# DMASS_DMSS_CRYPTO_AM61_CFG_CBASS_0_DMASS_DMSS_CRYPTO_AM61_CFG_CBASS_0_FW_450C8000h register map
Vendor: Texas Instruments
Peripheral module from a debugger description file (folder am62L).
Registers are 32-bit, read-write, reset 0x0 unless marked. A register's access mark holds for its fields unless they carry their own. Offsets are as the file gives them; lines under a group give offsets from that group; [hi:lo] are bit positions; {n}, {i} and the like mark numbered series; 'fields as' and 'values as' point back to an identical list; <NAME> marks a mode.

## DMASS_DMSS_CRYPTO_AM61_CFG_CBASS_0_FW
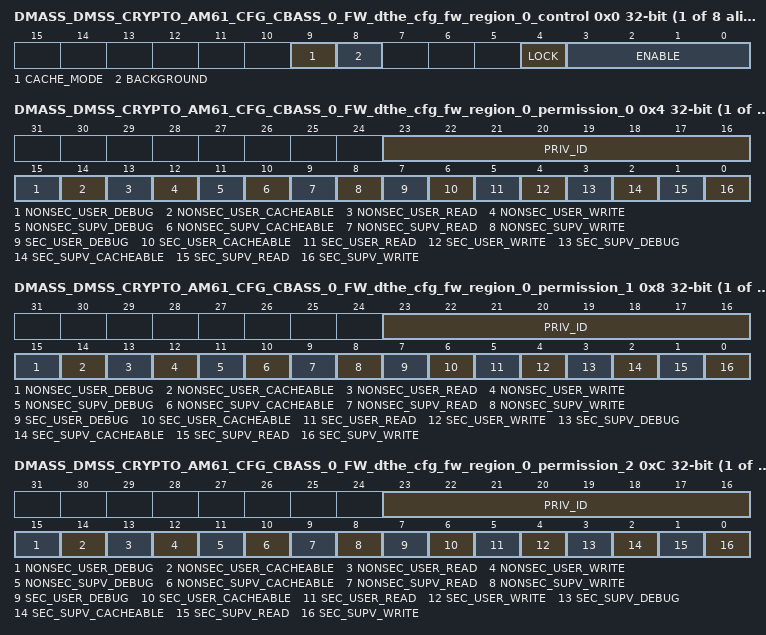
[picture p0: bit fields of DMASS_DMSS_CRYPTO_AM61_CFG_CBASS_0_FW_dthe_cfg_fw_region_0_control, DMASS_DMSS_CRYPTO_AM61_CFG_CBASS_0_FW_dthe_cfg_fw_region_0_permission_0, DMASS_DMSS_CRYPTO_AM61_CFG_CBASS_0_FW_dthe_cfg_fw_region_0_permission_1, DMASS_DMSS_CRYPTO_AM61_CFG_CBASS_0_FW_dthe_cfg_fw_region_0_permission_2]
{0x0+0x20*i} DMASS_DMSS_CRYPTO_AM61_CFG_CBASS_0_FW_dthe_cfg_fw_region_{i}_control access not given (i=0..7) — The FW Region {i} Control Register defines the control fields for the slave dthe.dthe_cfg region {i} firewall.
  [9] CACHE_MODE rw — Cache mode for region. Set to 1 to check cache permissions. Set to 0 to ignore cache permissions. Reset Source: vclk_mod_g_rst_n
  [8] BACKGROUND rw — Background enable for region. There can be 1 backgroun region per FW and foreground regions can have overlapping addresses only with the background region. Reset Source: vclk_mod_g_rst_n
  [4] LOCK — Lock region. Once set region values cannot be modified. Reset Source: vclk_mod_g_rst_n (access R/W1TS)
  [3:0] ENABLE rw — Enable region. A value of 0xA enables, others disable. Reset Source: vclk_mod_g_rst_n
{0x4+0x20*i} DMASS_DMSS_CRYPTO_AM61_CFG_CBASS_0_FW_dthe_cfg_fw_region_{i}_permission_0 (i=0..7) — The FW Region {i} Permission 0 Register defines the permissions for the slave dthe.dthe_cfg region {i} firewall.
  [23:16] PRIV_ID — Allowed privid. Reset Source: vclk_mod_g_rst_n
  [15] NONSEC_USER_DEBUG — Non-secure user debug allowed. Reset Source: vclk_mod_g_rst_n
  [14] NONSEC_USER_CACHEABLE — Non-secure user cacheable allowed. Reset Source: vclk_mod_g_rst_n
  [13] NONSEC_USER_READ — Non-secure user read allowed. Reset Source: vclk_mod_g_rst_n
  [12] NONSEC_USER_WRITE — Non-secure user write allowed. Reset Source: vclk_mod_g_rst_n
  [11] NONSEC_SUPV_DEBUG — Non-secure supervisor debug allowed. Reset Source: vclk_mod_g_rst_n
  [10] NONSEC_SUPV_CACHEABLE — Non-secure supervisor cacheable allowed. Reset Source: vclk_mod_g_rst_n
  [9] NONSEC_SUPV_READ — Non-secure supervisor read allowed. Reset Source: vclk_mod_g_rst_n
  [8] NONSEC_SUPV_WRITE — Non-secure supervisor write allowed. Reset Source: vclk_mod_g_rst_n
  [7] SEC_USER_DEBUG — Secure user debug allowed. Reset Source: vclk_mod_g_rst_n
  [6] SEC_USER_CACHEABLE — Secure user cacheable allowed. Reset Source: vclk_mod_g_rst_n
  [5] SEC_USER_READ — Secure user read allowed. Reset Source: vclk_mod_g_rst_n
  [4] SEC_USER_WRITE — Secure user write allowed. Reset Source: vclk_mod_g_rst_n
  [3] SEC_SUPV_DEBUG — Secure supervisor debug allowed. Reset Source: vclk_mod_g_rst_n
  [2] SEC_SUPV_CACHEABLE — Secure supervisor cacheable allowed. Reset Source: vclk_mod_g_rst_n
  [1] SEC_SUPV_READ — Secure supervisor read allowed. Reset Source: vclk_mod_g_rst_n
  [0] SEC_SUPV_WRITE — Secure supervisor write allowed. Reset Source: vclk_mod_g_rst_n
{0x8+0x20*i} DMASS_DMSS_CRYPTO_AM61_CFG_CBASS_0_FW_dthe_cfg_fw_region_{i}_permission_1 (i=0..7) — The FW Region {i} Permission 1 Register defines the permissions for the slave dthe.dthe_cfg region {i} firewall.
  fields as DMASS_DMSS_CRYPTO_AM61_CFG_CBASS_0_FW_dthe_cfg_fw_region_0_permission_0
{0xC+0x20*i} DMASS_DMSS_CRYPTO_AM61_CFG_CBASS_0_FW_dthe_cfg_fw_region_{i}_permission_2 (i=0..7) — The FW Region {i} Permission 2 Register defines the permissions for the slave dthe.dthe_cfg region {i} firewall.
  fields as DMASS_DMSS_CRYPTO_AM61_CFG_CBASS_0_FW_dthe_cfg_fw_region_0_permission_0
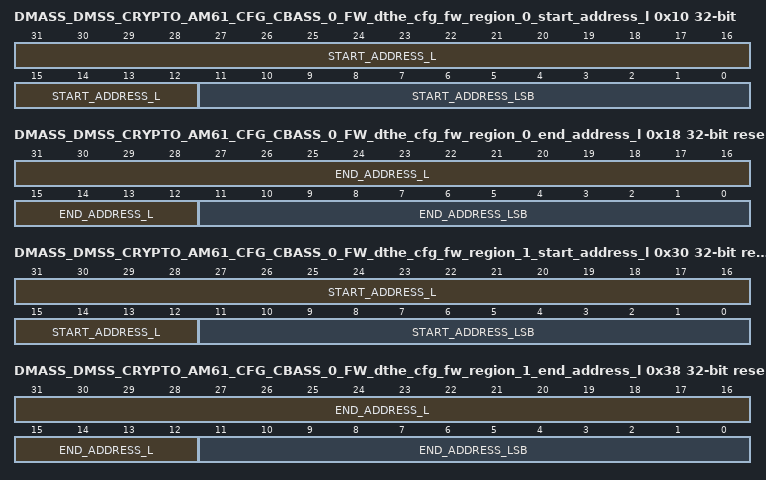
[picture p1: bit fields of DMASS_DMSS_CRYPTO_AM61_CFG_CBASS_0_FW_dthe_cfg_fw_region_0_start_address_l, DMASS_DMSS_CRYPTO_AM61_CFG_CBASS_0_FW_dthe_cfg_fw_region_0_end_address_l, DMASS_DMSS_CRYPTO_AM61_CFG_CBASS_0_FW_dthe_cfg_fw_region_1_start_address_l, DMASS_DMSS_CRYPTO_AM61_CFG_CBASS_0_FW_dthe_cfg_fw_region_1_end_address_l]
0x10 DMASS_DMSS_CRYPTO_AM61_CFG_CBASS_0_FW_dthe_cfg_fw_region_0_start_address_l access per field — The FW Region 0 Start Address Low Register defines the start address bits 31 to 0 for the slave dthe.dthe_cfg region 0 firewall.
  [31:12] START_ADDRESS_L rw — Start address bits 31 to 12. Lowest 12 bits are forced to 0 as address must be 4KB aligned. Reset Source: vclk_mod_g_rst_n
  [11:0] START_ADDRESS_LSB ro — Start address bits 11 to 0 are forced to 0 as address must be 4KB aligned. Reset Source: vclk_mod_g_rst_n
{0x14+0x20*i} DMASS_DMSS_CRYPTO_AM61_CFG_CBASS_0_FW_dthe_cfg_fw_region_{i}_start_address_h (i=0..7) — The FW Region {i} Start Address High Register defines the start address bits 47 to 32 for the slave dthe.dthe_cfg region {i} firewall.
  [15:0] START_ADDRESS_H — Start address bits 47 to 32. Reset Source: vclk_mod_g_rst_n
0x18 DMASS_DMSS_CRYPTO_AM61_CFG_CBASS_0_FW_dthe_cfg_fw_region_0_end_address_l access per field reset 0xFFF — The FW Region 0 End Address Low Register defines the end address bits 31 to 0 to include for the slave dthe.dthe_cfg region 0 firewall.
  [31:12] END_ADDRESS_L rw — End address bits 31 to 12 to include in the match. Lowest 12 bits are forced to 1s as address must be 4KB aligned. Reset Source: vclk_mod_g_rst_n
  [11:0] END_ADDRESS_LSB ro — End address bits 11 to 0 are forced to 1s as address must be 4KB aligned minus 1. Reset Source: vclk_mod_g_rst_n
{0x1C+0x20*i} DMASS_DMSS_CRYPTO_AM61_CFG_CBASS_0_FW_dthe_cfg_fw_region_{i}_end_address_h (i=0..7) — The FW Region {i} End Address High Register defines the end address bits 47 to 32 to include for the slave dthe.dthe_cfg region {i} firewall.
  [15:0] END_ADDRESS_H — End address bits 47 to 32 to include in the match. Reset Source: vclk_mod_g_rst_n
0x30 DMASS_DMSS_CRYPTO_AM61_CFG_CBASS_0_FW_dthe_cfg_fw_region_1_start_address_l access per field reset 0x1000 — The FW Region 1 Start Address Low Register defines the start address bits 31 to 0 for the slave dthe.dthe_cfg region 1 firewall.
  fields as DMASS_DMSS_CRYPTO_AM61_CFG_CBASS_0_FW_dthe_cfg_fw_region_0_start_address_l
0x38 DMASS_DMSS_CRYPTO_AM61_CFG_CBASS_0_FW_dthe_cfg_fw_region_1_end_address_l access per field reset 0x1FFF — The FW Region 1 End Address Low Register defines the end address bits 31 to 0 to include for the slave dthe.dthe_cfg region 1 firewall.
  fields as DMASS_DMSS_CRYPTO_AM61_CFG_CBASS_0_FW_dthe_cfg_fw_region_0_end_address_l
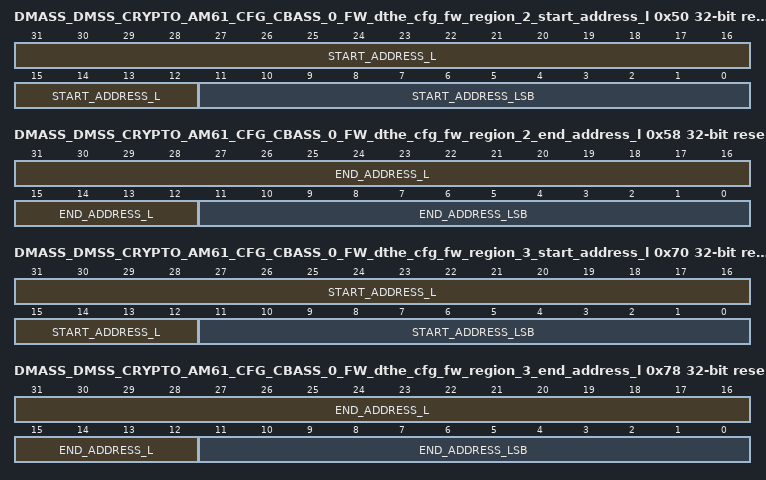
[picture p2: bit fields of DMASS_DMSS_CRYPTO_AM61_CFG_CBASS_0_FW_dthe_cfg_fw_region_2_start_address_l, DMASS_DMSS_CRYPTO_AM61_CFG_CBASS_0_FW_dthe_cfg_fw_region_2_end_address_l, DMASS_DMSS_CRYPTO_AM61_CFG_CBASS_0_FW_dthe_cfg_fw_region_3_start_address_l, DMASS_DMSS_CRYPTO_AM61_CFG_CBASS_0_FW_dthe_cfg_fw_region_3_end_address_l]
0x50 DMASS_DMSS_CRYPTO_AM61_CFG_CBASS_0_FW_dthe_cfg_fw_region_2_start_address_l access per field reset 0x2000 — The FW Region 2 Start Address Low Register defines the start address bits 31 to 0 for the slave dthe.dthe_cfg region 2 firewall.
  fields as DMASS_DMSS_CRYPTO_AM61_CFG_CBASS_0_FW_dthe_cfg_fw_region_0_start_address_l
0x58 DMASS_DMSS_CRYPTO_AM61_CFG_CBASS_0_FW_dthe_cfg_fw_region_2_end_address_l access per field reset 0x2FFF — The FW Region 2 End Address Low Register defines the end address bits 31 to 0 to include for the slave dthe.dthe_cfg region 2 firewall.
  fields as DMASS_DMSS_CRYPTO_AM61_CFG_CBASS_0_FW_dthe_cfg_fw_region_0_end_address_l
0x70 DMASS_DMSS_CRYPTO_AM61_CFG_CBASS_0_FW_dthe_cfg_fw_region_3_start_address_l access per field reset 0x6000 — The FW Region 3 Start Address Low Register defines the start address bits 31 to 0 for the slave dthe.dthe_cfg region 3 firewall.
  fields as DMASS_DMSS_CRYPTO_AM61_CFG_CBASS_0_FW_dthe_cfg_fw_region_0_start_address_l
0x78 DMASS_DMSS_CRYPTO_AM61_CFG_CBASS_0_FW_dthe_cfg_fw_region_3_end_address_l access per field reset 0x6FFF — The FW Region 3 End Address Low Register defines the end address bits 31 to 0 to include for the slave dthe.dthe_cfg region 3 firewall.
  fields as DMASS_DMSS_CRYPTO_AM61_CFG_CBASS_0_FW_dthe_cfg_fw_region_0_end_address_l
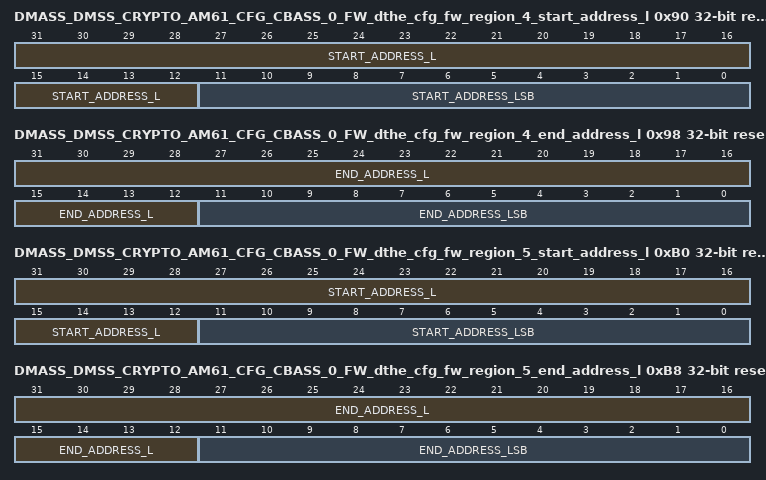
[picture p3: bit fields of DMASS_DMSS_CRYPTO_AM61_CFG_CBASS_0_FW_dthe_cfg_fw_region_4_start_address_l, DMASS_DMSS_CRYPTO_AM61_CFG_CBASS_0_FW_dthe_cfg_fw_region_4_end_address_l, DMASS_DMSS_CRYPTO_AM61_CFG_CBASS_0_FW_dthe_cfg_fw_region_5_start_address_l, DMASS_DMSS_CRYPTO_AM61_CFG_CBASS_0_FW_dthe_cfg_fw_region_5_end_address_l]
0x90 DMASS_DMSS_CRYPTO_AM61_CFG_CBASS_0_FW_dthe_cfg_fw_region_4_start_address_l access per field reset 0x7000 — The FW Region 4 Start Address Low Register defines the start address bits 31 to 0 for the slave dthe.dthe_cfg region 4 firewall.
  fields as DMASS_DMSS_CRYPTO_AM61_CFG_CBASS_0_FW_dthe_cfg_fw_region_0_start_address_l
0x98 DMASS_DMSS_CRYPTO_AM61_CFG_CBASS_0_FW_dthe_cfg_fw_region_4_end_address_l access per field reset 0x7FFF — The FW Region 4 End Address Low Register defines the end address bits 31 to 0 to include for the slave dthe.dthe_cfg region 4 firewall.
  fields as DMASS_DMSS_CRYPTO_AM61_CFG_CBASS_0_FW_dthe_cfg_fw_region_0_end_address_l
0xB0 DMASS_DMSS_CRYPTO_AM61_CFG_CBASS_0_FW_dthe_cfg_fw_region_5_start_address_l access per field reset 0x4000 — The FW Region 5 Start Address Low Register defines the start address bits 31 to 0 for the slave dthe.dthe_cfg region 5 firewall.
  fields as DMASS_DMSS_CRYPTO_AM61_CFG_CBASS_0_FW_dthe_cfg_fw_region_0_start_address_l
0xB8 DMASS_DMSS_CRYPTO_AM61_CFG_CBASS_0_FW_dthe_cfg_fw_region_5_end_address_l access per field reset 0x4FFF — The FW Region 5 End Address Low Register defines the end address bits 31 to 0 to include for the slave dthe.dthe_cfg region 5 firewall.
  fields as DMASS_DMSS_CRYPTO_AM61_CFG_CBASS_0_FW_dthe_cfg_fw_region_0_end_address_l
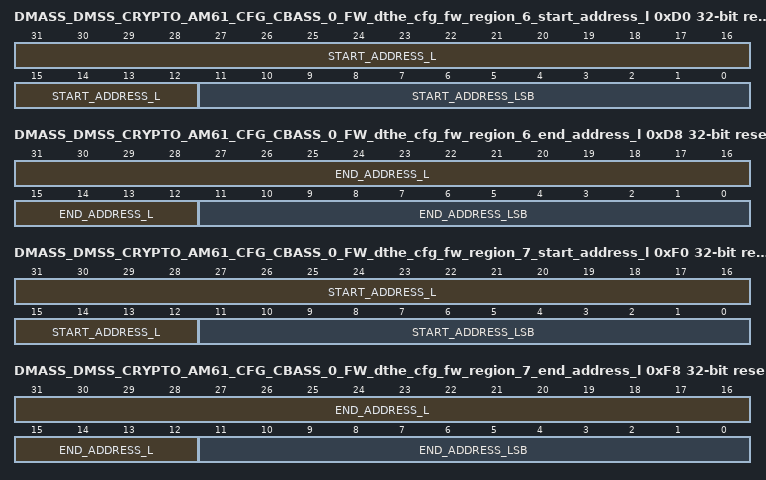
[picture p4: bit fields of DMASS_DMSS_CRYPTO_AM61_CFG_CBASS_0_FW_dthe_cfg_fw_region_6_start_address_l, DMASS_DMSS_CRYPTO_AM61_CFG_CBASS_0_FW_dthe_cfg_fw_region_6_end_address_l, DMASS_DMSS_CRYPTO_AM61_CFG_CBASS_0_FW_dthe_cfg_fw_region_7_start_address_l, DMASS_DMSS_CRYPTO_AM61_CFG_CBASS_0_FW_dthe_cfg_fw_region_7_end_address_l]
0xD0 DMASS_DMSS_CRYPTO_AM61_CFG_CBASS_0_FW_dthe_cfg_fw_region_6_start_address_l access per field reset 0x5000 — The FW Region 6 Start Address Low Register defines the start address bits 31 to 0 for the slave dthe.dthe_cfg region 6 firewall.
  fields as DMASS_DMSS_CRYPTO_AM61_CFG_CBASS_0_FW_dthe_cfg_fw_region_0_start_address_l
0xD8 DMASS_DMSS_CRYPTO_AM61_CFG_CBASS_0_FW_dthe_cfg_fw_region_6_end_address_l access per field reset 0x5FFF — The FW Region 6 End Address Low Register defines the end address bits 31 to 0 to include for the slave dthe.dthe_cfg region 6 firewall.
  fields as DMASS_DMSS_CRYPTO_AM61_CFG_CBASS_0_FW_dthe_cfg_fw_region_0_end_address_l
0xF0 DMASS_DMSS_CRYPTO_AM61_CFG_CBASS_0_FW_dthe_cfg_fw_region_7_start_address_l access per field reset 0xA000 — The FW Region 7 Start Address Low Register defines the start address bits 31 to 0 for the slave dthe.dthe_cfg region 7 firewall.
  fields as DMASS_DMSS_CRYPTO_AM61_CFG_CBASS_0_FW_dthe_cfg_fw_region_0_start_address_l
0xF8 DMASS_DMSS_CRYPTO_AM61_CFG_CBASS_0_FW_dthe_cfg_fw_region_7_end_address_l access per field reset 0xAFFF — The FW Region 7 End Address Low Register defines the end address bits 31 to 0 to include for the slave dthe.dthe_cfg region 7 firewall.
  fields as DMASS_DMSS_CRYPTO_AM61_CFG_CBASS_0_FW_dthe_cfg_fw_region_0_end_address_l
